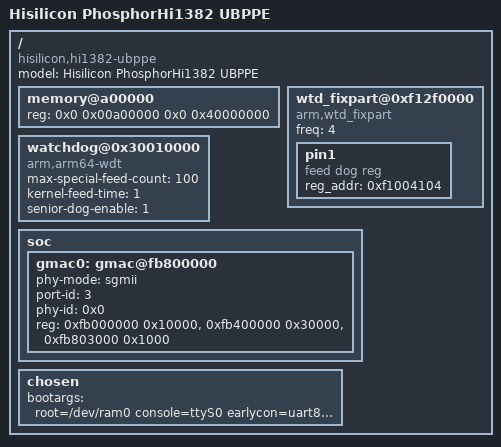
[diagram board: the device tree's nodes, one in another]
/**
 * dts file for Hisilicon PhosphorHi1382 UBPPE
 *
 * Copyright (C) 2015,2016 Hisilicon Ltd.
 *
 * This program is free software; you can redistribute it and/or modify
 * it under the terms of the GNU General Public License version 2 as
 * publishhed by the Free Software Foundation.
 *
 */

/dts-v1/;

/include/ "hi1382.dtsi"

/ {
	model = "Hisilicon PhosphorHi1382 UBPPE";
	compatible = "hisilicon,hi1382-ubppe", "hisilicon,hi1382";

	memory@a00000 {
		device_type = "memory";
		reg = <0x0 0x00a00000 0x0 0x40000000>;
	};

        wtd_fixpart@0xf12f0000 {
               compatible = "arm,wtd_fixpart";
               freq = <4>;
               #address-cells = <2>;
               #size-cells = <2>;
               ranges;

               pin1 {
                        compatible = "feed dog reg";
                        reg_addr = <0xf1004104>;
               };
        };

        watchdog@0x30010000 {
            compatible = "arm,arm64-wdt";
            max-special-feed-count = <100>;
            kernel-feed-time = <1>;
            senior-dog-enable = <1>;
	};

	soc {
		gmac0: gmac@fb800000 {
			phy-mode = "sgmii";
			port-id = <3>;
			phy-id = <0x0>;
			reg = <0xfb000000 0x10000>,
			<0xfb400000 0x30000>,
			<0xfb803000 0x1000>;
		};
	};

	chosen {
		bootargs = "root=/dev/ram0 console=ttyS0 earlycon=uart8250,mmio32,0xf1300000 quiet initrd=0x3800040,128M";
	};
};
